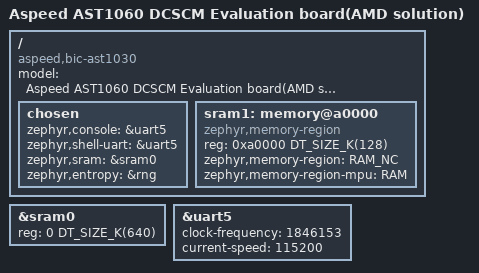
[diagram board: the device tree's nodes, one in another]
/*
 * Copyright (c) 2021 ASPEED Technology Inc.
 *
 * SPDX-License-Identifier: Apache-2.0
 */

/dts-v1/;
#include <aspeed/ast10x0.dtsi>

/ {
	model = "Aspeed AST1060 DCSCM Evaluation board(AMD solution)";
	compatible = "aspeed,bic-ast1030", "aspeed,ast1030";

	chosen {
		zephyr,console = &uart5;
		zephyr,shell-uart = &uart5;
		zephyr,sram = &sram0;
		zephyr,entropy = &rng;
	};

	sram1: memory@a0000 {
		compatible = "zephyr,memory-region", "mmio-sram";
		device_type = "memory";
		reg = <0xa0000 DT_SIZE_K(128)>;
		zephyr,memory-region = "RAM_NC";
		zephyr,memory-region-mpu = "RAM";
	};
};

&sram0 {
	reg = <0 DT_SIZE_K(640)>;
};

&uart5 {
	clock-frequency = <1846153>;
	current-speed = <115200>;
};

